# C2000_Enhanced_Debug_Counter_Registers register map
Vendor: Texas Instruments
Peripheral module from a debugger description file (folder C2000).
Address unit: 16 bits
Registers are 16-bit, access not given, no defined reset value unless marked. A register's access mark holds for its fields unless they carry their own. Offsets are as the file gives them; lines under a group give offsets from that group; [hi:lo] are bit positions; {n}, {i} and the like mark numbered series; 'fields as' and 'values as' point back to an identical list; <NAME> marks a mode.

## EnhancedDebugHWBPRegs — Enhanced Debug HWBP Registers
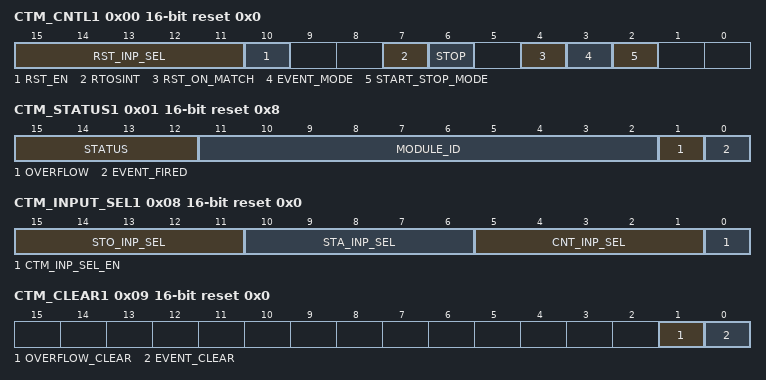
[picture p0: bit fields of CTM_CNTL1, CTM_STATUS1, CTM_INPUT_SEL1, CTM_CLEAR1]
0x00 CTM_CNTL1 rw reset 0x0
  [15:11] RST_INP_SEL — Reset Input select
  [10] RST_EN — Enable Reset
  [7] RTOSINT — RTOSINT bit
  [6] STOP — Stop bit (Halt/No Halt of CPU) range=
  [4] RST_ON_MATCH — Reset on match bit
  [3] EVENT_MODE — Event mode bit
  [2] START_STOP_MODE — Start/stop mode bit
0x01 CTM_STATUS1 ro reset 0x8
  [15:12] STATUS — Status bits
  [11:2] MODULE_ID — Identification bits
  [1] OVERFLOW — Counter Overflowed
  [0] EVENT_FIRED — Counter Event Fired bits
0x02 CTM_REF_LOW1 — Lower 16 bits of the counter reference value.
0x03 CTM_REF_HIGH1 — Higher 16 bits of the counter reference value.
0x04 CTM_COUNT_LOW1 — Lower 16 bits of the current count value.
0x05 CTM_COUNT_HIGH1 — Higher 16 bits of the current count value.
0x06 CTM_MAX_COUNT_LOW1 — Lower 16 bits of the maximum recorded counter value.
0x07 CTM_MAX_COUNT_HIGH1 — Higher 16 bits of the maximum recorded counter value.
0x08 CTM_INPUT_SEL1 rw reset 0x0
  [15:11] STO_INP_SEL — Stop input select
  [10:6] STA_INP_SEL — Start input select
  [5:1] CNT_INP_SEL — Count input select
  [0] CTM_INP_SEL_EN — Count input select enable
0x09 CTM_CLEAR1 rw reset 0x0
  [1] OVERFLOW_CLEAR — Clear OVERFLOW
  [0] EVENT_CLEAR — Clear EVENT_FIRED
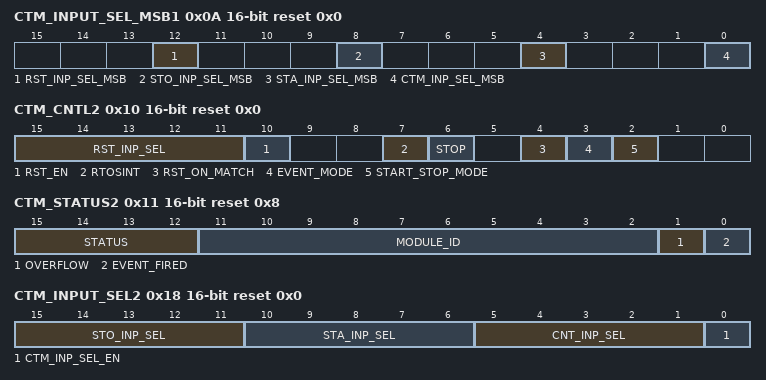
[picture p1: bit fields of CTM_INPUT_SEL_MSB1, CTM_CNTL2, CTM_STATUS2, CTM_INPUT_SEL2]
0x0A CTM_INPUT_SEL_MSB1 rw reset 0x0
  [12] RST_INP_SEL_MSB — Reset Input Select
  [8] STO_INP_SEL_MSB — Stop Input Select
  [4] STA_INP_SEL_MSB — Start Input Select
  [0] CTM_INP_SEL_MSB — Count Input Select
0x10 CTM_CNTL2 rw reset 0x0
  fields as CTM_CNTL1
0x11 CTM_STATUS2 ro reset 0x8
  fields as CTM_STATUS1
0x12 CTM_REF_LOW2 — Lower 16 bits of the counter reference value.
0x13 CTM_REF_HIGH2 — Higher 16 bits of the counter reference value.
0x14 CTM_COUNT_LOW2 — Lower 16 bits of the current count value.
0x15 CTM_COUNT_HIGH2 — Higher 16 bits of the current count value.
0x16 CTM_MAX_COUNT_LOW2 — Lower 16 bits of the maximum recorded counter value.
0x17 CTM_MAX_COUNT_HIGH2 — Higher 16 bits of the maximum recorded counter value.
0x18 CTM_INPUT_SEL2 rw reset 0x0
  fields as CTM_INPUT_SEL1
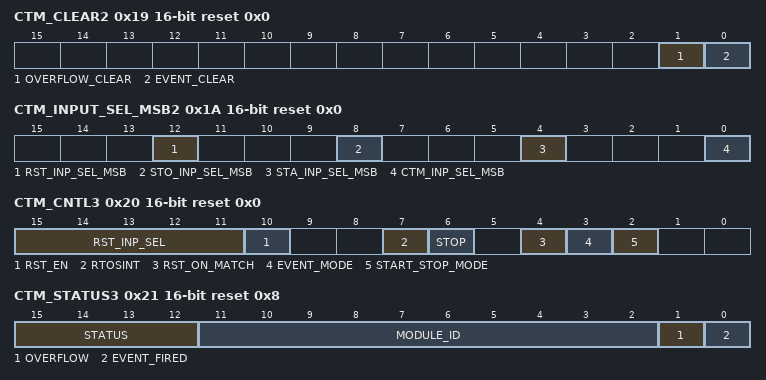
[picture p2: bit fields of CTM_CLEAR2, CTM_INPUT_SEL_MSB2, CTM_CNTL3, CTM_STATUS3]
0x19 CTM_CLEAR2 rw reset 0x0
  fields as CTM_CLEAR1
0x1A CTM_INPUT_SEL_MSB2 rw reset 0x0
  fields as CTM_INPUT_SEL_MSB1
0x20 CTM_CNTL3 rw reset 0x0
  fields as CTM_CNTL1
0x21 CTM_STATUS3 ro reset 0x8
  fields as CTM_STATUS1
0x22 CTM_REF_LOW3 — Lower 16 bits of the counter reference value.
0x23 CTM_REF_HIGH3 — Higher 16 bits of the counter reference value.
0x24 CTM_COUNT_LOW3 — Lower 16 bits of the current count value.
0x25 CTM_COUNT_HIGH3 — Higher 16 bits of the current count value.
0x26 CTM_MAX_COUNT_LOW3 — Lower 16 bits of the maximum recorded counter value.
0x27 CTM_MAX_COUNT_HIGH3 — Higher 16 bits of the maximum recorded counter value.
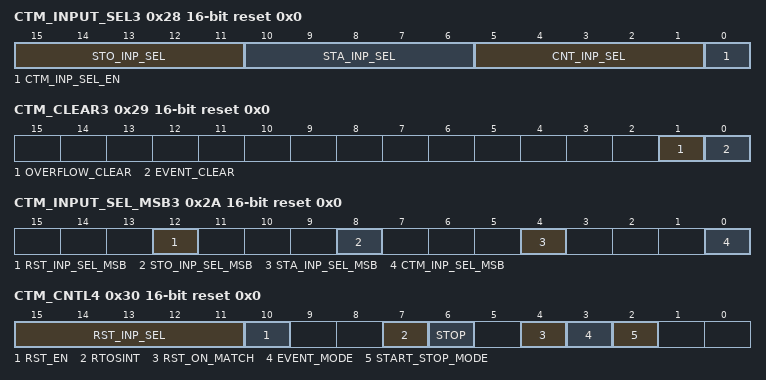
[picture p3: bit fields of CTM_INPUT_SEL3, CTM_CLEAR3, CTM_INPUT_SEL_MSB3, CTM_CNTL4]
0x28 CTM_INPUT_SEL3 rw reset 0x0
  fields as CTM_INPUT_SEL1
0x29 CTM_CLEAR3 rw reset 0x0
  fields as CTM_CLEAR1
0x2A CTM_INPUT_SEL_MSB3 rw reset 0x0
  fields as CTM_INPUT_SEL_MSB1
0x30 CTM_CNTL4 rw reset 0x0
  fields as CTM_CNTL1
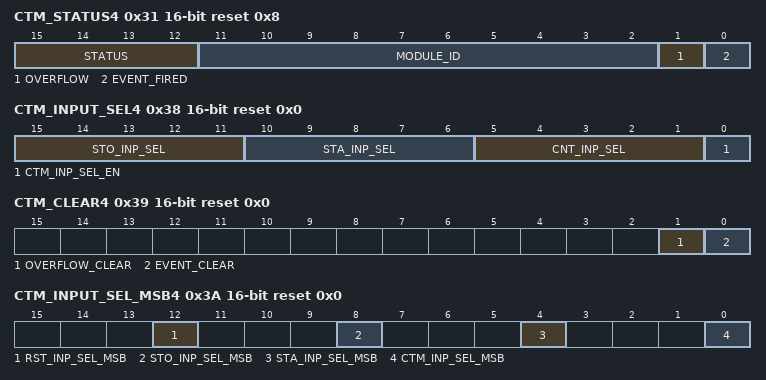
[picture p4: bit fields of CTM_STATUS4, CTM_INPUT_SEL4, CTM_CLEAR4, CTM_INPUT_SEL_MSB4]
0x31 CTM_STATUS4 ro reset 0x8
  fields as CTM_STATUS1
0x32 CTM_REF_LOW4 — Lower 16 bits of the counter reference value.
0x33 CTM_REF_HIGH4 — Higher 16 bits of the counter reference value.
0x34 CTM_COUNT_LOW4 — Lower 16 bits of the current count value.
0x35 CTM_COUNT_HIGH4 — Higher 16 bits of the current count value.
0x36 CTM_MAX_COUNT_LOW4 — Lower 16 bits of the maximum recorded counter value.
0x37 CTM_MAX_COUNT_HIGH4 — Higher 16 bits of the maximum recorded counter value.
0x38 CTM_INPUT_SEL4 rw reset 0x0
  fields as CTM_INPUT_SEL1
0x39 CTM_CLEAR4 rw reset 0x0
  fields as CTM_CLEAR1
0x3A CTM_INPUT_SEL_MSB4 rw reset 0x0
  fields as CTM_INPUT_SEL_MSB1
